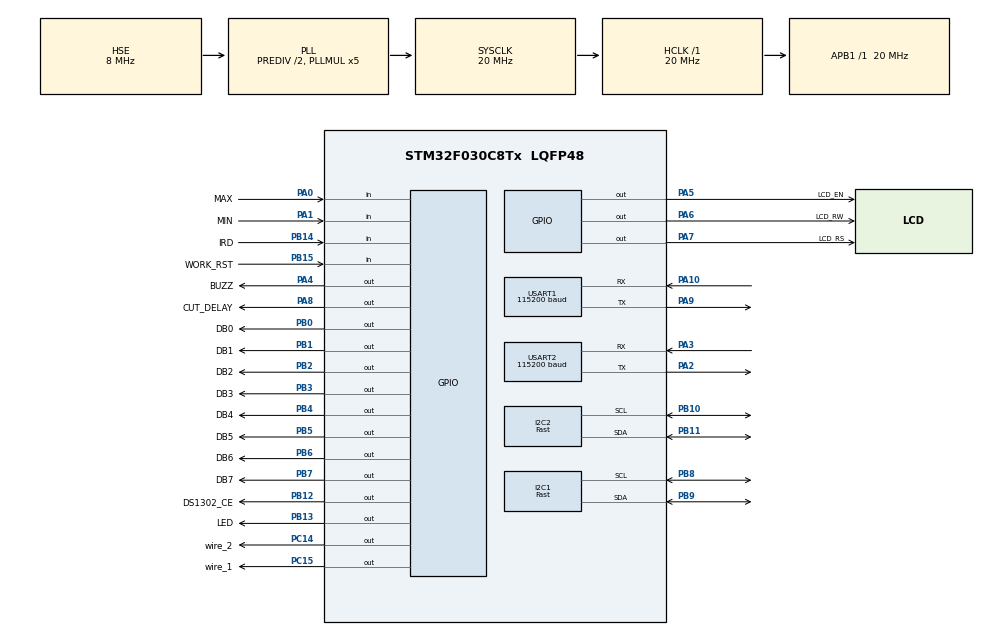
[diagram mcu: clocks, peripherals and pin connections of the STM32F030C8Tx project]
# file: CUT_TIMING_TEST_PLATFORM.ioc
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I2C1.I2C_Speed_Mode=I2C_Fast
I2C1.Timing=0x00100822
I2C2.I2C_Speed_Mode=I2C_Fast
I2C2.Timing=0x00100822
Mcu.Family=STM32F0
Mcu.Name=STM32F030C8Tx
Mcu.Package=LQFP48
NVIC.USART1_IRQn=true\:0\:0\:false\:false\:true\:true\:true\:true
NVIC.USART2_IRQn=true\:0\:0\:false\:false\:true\:true\:true\:true
PA0.GPIO_Label=MAX
PA0.Signal=GPIO_Input
PA1.GPIO_Label=MIN
PA1.Signal=GPIO_Input
PA10.Mode=Asynchronous
PA10.Signal=USART1_RX
PA13.Mode=Serial_Wire
PA13.Signal=SYS_SWDIO
PA14.Mode=Serial_Wire
PA14.Signal=SYS_SWCLK
PA2.Mode=Asynchronous
PA2.Signal=USART2_TX
PA3.Mode=Asynchronous
PA3.Signal=USART2_RX
PA4.GPIO_Label=BUZZ
PA4.Signal=GPIO_Output
PA5.GPIO_Label=LCD_EN
PA5.Signal=GPIO_Output
PA6.GPIO_Label=LCD_RW
PA6.Signal=GPIO_Output
PA7.GPIO_Label=LCD_RS
PA7.Signal=GPIO_Output
PA8.GPIO_Label=CUT_DELAY
PA8.Signal=GPIO_Output
PA9.Mode=Asynchronous
PA9.Signal=USART1_TX
PB0.GPIO_Label=DB0
PB0.Signal=GPIO_Output
PB1.GPIO_Label=DB1
PB1.Signal=GPIO_Output
PB10.Mode=I2C
PB10.Signal=I2C2_SCL
PB11.Mode=I2C
PB11.Signal=I2C2_SDA
PB12.GPIO_Label=DS1302_CE
PB12.Signal=GPIO_Output
PB13.GPIO_Label=LED
PB13.Signal=GPIO_Output
PB14.GPIO_Label=IRD
PB14.Signal=GPIO_Input
PB15.GPIO_Label=WORK_RST
PB15.Signal=GPIO_Input
PB2.GPIO_Label=DB2
PB2.Signal=GPIO_Output
PB3.GPIO_Label=DB3
PB3.Signal=GPIO_Output
PB4.GPIO_Label=DB4
PB4.Signal=GPIO_Output
PB5.GPIO_Label=DB5
PB5.Signal=GPIO_Output
PB6.GPIO_Label=DB6
PB6.Signal=GPIO_Output
PB7.GPIO_Label=DB7
PB7.Signal=GPIO_Output
PB8.Mode=I2C
PB8.Signal=I2C1_SCL
PB9.Mode=I2C
PB9.Signal=I2C1_SDA
PC14-OSC32_IN.GPIO_Label=wire_2
PC14-OSC32_IN.Signal=GPIO_Output
PC15-OSC32_OUT.GPIO_Label=wire_1
PC15-OSC32_OUT.Signal=GPIO_Output
PF0-OSC_IN.Mode=HSE-External-Oscillator
PF0-OSC_IN.Signal=RCC_OSC_IN
PF1-OSC_OUT.Mode=HSE-External-Oscillator
PF1-OSC_OUT.Signal=RCC_OSC_OUT
ProjectManager.HeapSize=0x200
ProjectManager.StackSize=0x400
ProjectManager.TargetToolchain=MDK-ARM V5.32
RCC.AHBFreq_Value=20000000
RCC.APB1Freq_Value=20000000
RCC.APB1TimFreq_Value=20000000
RCC.HCLKFreq_Value=20000000
RCC.I2c1ClockSelection=RCC_I2C1CLKSOURCE_SYSCLK
RCC.PLLDivider=RCC_PREDIV_DIV2
RCC.PLLMUL=RCC_PLL_MUL5
RCC.PLLSourceVirtual=RCC_PLLSOURCE_HSE
RCC.SYSCLKFreq_VALUE=20000000
RCC.SYSCLKSource=RCC_SYSCLKSOURCE_PLLCLK
USART1.BaudRate=115200
USART1.VirtualMode-Asynchronous=VM_ASYNC
USART2.BaudRate=115200
USART2.VirtualMode-Asynchronous=VM_ASYNC
board=custom

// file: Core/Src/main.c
/* USER CODE BEGIN Header */
/**
  ******************************************************************************
  * @file           : main.c
  * @brief          : Main program body
  ******************************************************************************
  * @attention
  *
  * Copyright (c) 2023 STMicroelectronics.
  * All rights reserved.
  *
  * This software is licensed under terms that can be found in the LICENSE file
  * in the root directory of this software component.
  * If no LICENSE file comes with this software, it is provided AS-IS.
  *
  ******************************************************************************
  */
/* USER CODE END Header */
#include "main.h"
#include "i2c.h"
#include "usart.h"
#include "gpio.h"

/* USER CODE BEGIN Includes */
#include "main_run.h"
/* USER CODE END Includes */

void SystemClock_Config(void);

int main(void)
{

  /* MCU Configuration--------------------------------------------------------*/

  /* Reset of all peripherals, Initializes the Flash interface and the Systick. */
  HAL_Init();

  /* Configure the system clock */
  SystemClock_Config();

  /* Initialize all configured peripherals */
  MX_GPIO_Init();
  MX_I2C1_Init();
  MX_I2C2_Init();
  MX_USART1_UART_Init();
  MX_USART2_UART_Init();
  /* USER CODE BEGIN 2 */
  main_run();
  /* USER CODE END 2 */

  /* Infinite loop */
  while (1)
  {

  }
}

void SystemClock_Config(void)
{
  RCC_OscInitTypeDef RCC_OscInitStruct = {0};
  RCC_ClkInitTypeDef RCC_ClkInitStruct = {0};
  RCC_PeriphCLKInitTypeDef PeriphClkInit = {0};

  /** Initializes the RCC Oscillators according to the specified parameters
  * in the RCC_OscInitTypeDef structure.
  */
  RCC_OscInitStruct.OscillatorType = RCC_OSCILLATORTYPE_HSE;
  RCC_OscInitStruct.HSEState = RCC_HSE_ON;
  RCC_OscInitStruct.PLL.PLLState = RCC_PLL_ON;
  RCC_OscInitStruct.PLL.PLLSource = RCC_PLLSOURCE_HSE;
  RCC_OscInitStruct.PLL.PLLMUL = RCC_PLL_MUL5;
  RCC_OscInitStruct.PLL.PREDIV = RCC_PREDIV_DIV2;
  if (HAL_RCC_OscConfig(&RCC_OscInitStruct) != HAL_OK)
  {
    Error_Handler();
  }

  /** Initializes the CPU, AHB and APB buses clocks
  */
  RCC_ClkInitStruct.ClockType = RCC_CLOCKTYPE_HCLK|RCC_CLOCKTYPE_SYSCLK
                              |RCC_CLOCKTYPE_PCLK1;
  RCC_ClkInitStruct.SYSCLKSource = RCC_SYSCLKSOURCE_PLLCLK;
  RCC_ClkInitStruct.AHBCLKDivider = RCC_SYSCLK_DIV1;
  RCC_ClkInitStruct.APB1CLKDivider = RCC_HCLK_DIV1;

  if (HAL_RCC_ClockConfig(&RCC_ClkInitStruct, FLASH_LATENCY_0) != HAL_OK)
  {
    Error_Handler();
  }
  PeriphClkInit.PeriphClockSelection = RCC_PERIPHCLK_USART1|RCC_PERIPHCLK_I2C1;
  PeriphClkInit.Usart1ClockSelection = RCC_USART1CLKSOURCE_PCLK1;
  PeriphClkInit.I2c1ClockSelection = RCC_I2C1CLKSOURCE_SYSCLK;
  if (HAL_RCCEx_PeriphCLKConfig(&PeriphClkInit) != HAL_OK)
  {
    Error_Handler();
  }
}

void Error_Handler(void)
{
  __disable_irq();
  while (1)
  {
  }
}
